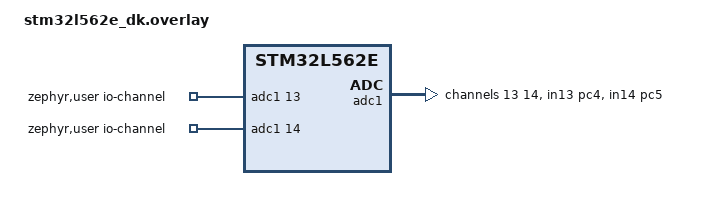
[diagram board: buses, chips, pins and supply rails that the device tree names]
/*
 * SPDX-License-Identifier: Apache-2.0
 *
 * Copyright (c) Benjamin Björnsson <benjamin.bjornsson@gmail.com>
 */

/ {
	zephyr,user {
		/* adjust channel number according to pinmux in board.dts */
		io-channels = <&adc1 13>, <&adc1 14>;
	};
};

&adc1 {
	pinctrl-0 = <&adc1_in13_pc4 &adc1_in14_pc5>;
	#address-cells = <1>;
	#size-cells = <0>;

	channel@d {
		reg = <13>;
		zephyr,gain = "ADC_GAIN_1";
		zephyr,reference = "ADC_REF_INTERNAL";
		zephyr,acquisition-time = <ADC_ACQ_TIME_MAX>;
		zephyr,resolution = <12>;
	};

	channel@e {
		reg = <14>;
		zephyr,gain = "ADC_GAIN_1";
		zephyr,reference = "ADC_REF_INTERNAL";
		zephyr,acquisition-time = <ADC_ACQ_TIME_MAX>;
		zephyr,resolution = <12>;
	};
};
